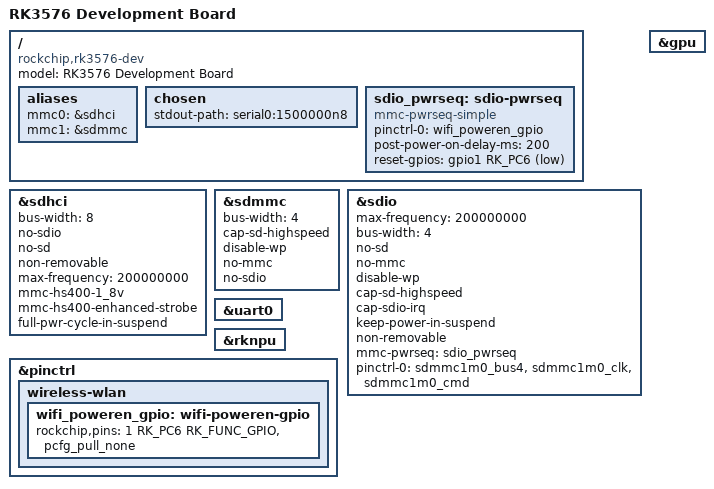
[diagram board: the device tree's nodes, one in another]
// SPDX-License-Identifier: (GPL-2.0+ OR MIT)
/* RK3576 development target: serial, eMMC, SD and SDIO WiFi (AP6275P). */
/dts-v1/;
#include <dt-bindings/gpio/gpio.h>
#include <dt-bindings/pinctrl/rockchip.h>
#include "rk3576.dtsi"

/ {
	model = "RK3576 Development Board";
	compatible = "rockchip,rk3576-dev", "rockchip,rk3576";

	aliases {
		mmc0 = &sdhci;
		mmc1 = &sdmmc;
	};

	chosen {
		stdout-path = "serial0:1500000n8";
	};

	/* Mainline-standard WiFi power sequencing (wlan-platdata is not in this kernel). */
	sdio_pwrseq: sdio-pwrseq {
		compatible = "mmc-pwrseq-simple";
		pinctrl-names = "default";
		pinctrl-0 = <&wifi_poweren_gpio>;
		post-power-on-delay-ms = <200>;
		reset-gpios = <&gpio1 RK_PC6 GPIO_ACTIVE_LOW>;
	};
};

&sdhci {
	bus-width = <8>;
	no-sdio;
	no-sd;
	non-removable;
	max-frequency = <200000000>;
	mmc-hs400-1_8v;
	mmc-hs400-enhanced-strobe;
	full-pwr-cycle-in-suspend;
	status = "okay";
};

&sdmmc {
	bus-width = <4>;
	cap-sd-highspeed;
	disable-wp;
	no-mmc;
	no-sdio;
	status = "okay";
};

&sdio {
	max-frequency = <200000000>;
	bus-width = <4>;
	no-sd;
	no-mmc;
	disable-wp;
	cap-sd-highspeed;
	cap-sdio-irq;
	keep-power-in-suspend;
	non-removable;
	mmc-pwrseq = <&sdio_pwrseq>;
	pinctrl-names = "default";
	pinctrl-0 = <&sdmmc1m0_bus4 &sdmmc1m0_clk &sdmmc1m0_cmd>;
	status = "okay";
};

&uart0 {
	status = "okay";
};

/* RK3576 GPU (Mali-G310 Bifrost) and NPU (RKNN) — enabled without PMIC
 * supply nodes; the board uses fixed rails. */
&gpu {
	status = "okay";
};

&rknpu {
	status = "okay";
};

&pinctrl {
	wireless-wlan {
		wifi_poweren_gpio: wifi-poweren-gpio {
			rockchip,pins = <1 RK_PC6 RK_FUNC_GPIO &pcfg_pull_none>;
		};
	};
};
